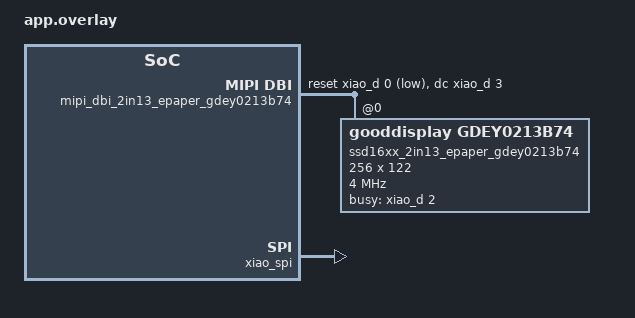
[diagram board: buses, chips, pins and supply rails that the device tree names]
/ {
	chosen {
		zephyr,display = &ssd16xx_2in13_epaper_gdey0213b74;
	};

	mipi_dbi_2in13_epaper_gdey0213b74 {
		compatible = "zephyr,mipi-dbi-spi";
		spi-dev = <&xiao_spi>;
		dc-gpios = <&xiao_d 3 GPIO_ACTIVE_HIGH>;
		reset-gpios = <&xiao_d 0 GPIO_ACTIVE_LOW>;	
		#address-cells = <1>;
		#size-cells = <0>;

		ssd16xx_2in13_epaper_gdey0213b74: ssd16xxfb@0 {
			compatible = "gooddisplay,gdey0213b74", "solomon,ssd1680";
			mipi-max-frequency = <4000000>;
			reg = <0>;
			/* Adjust to an integer multiple of 8, the actual resolution is 250x122.*/
			width = <256>; 
			height = <122>;
			busy-gpios = <&xiao_d 2 GPIO_ACTIVE_HIGH>;	/* D7 */

			tssv = <0x80>;

			full {
				border-waveform = <0x05>;
			};

			partial {
				border-waveform = <0x3c>;
			};
		};
	};
};

&xiao_spi {
    status = "okay";
	cs-gpios = <&xiao_d 1 GPIO_ACTIVE_LOW>;
};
